# M2Sxxx register map
Vendor: Microsemi; Series: SmartFusion2; File version: 2.0.32
CPU: CM3 r2p1, little endian, MPU, no FPU, 4 interrupt priority bits
Registers are 32-bit, read-write, no defined reset value unless marked. A register's access mark holds for its fields unless they carry their own. Offsets are from the block's base; [hi:lo] are bit positions; {n}, {i} and the like mark numbered series.

## SERDES_0_SYS_REG — No description provided for this peripheral
Base 0x4002A000
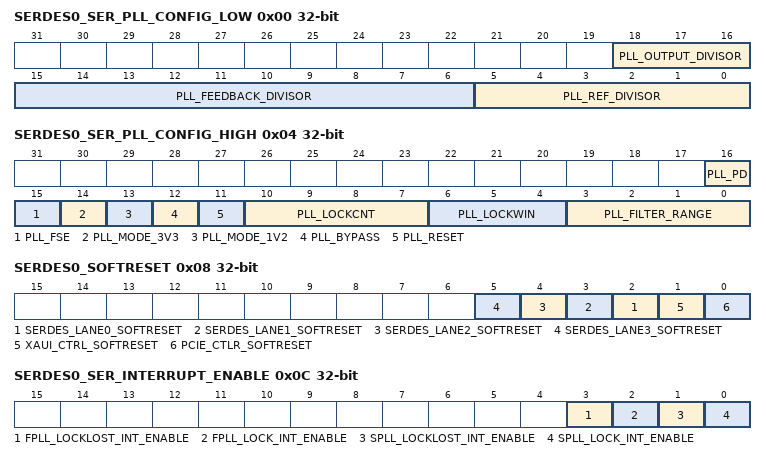
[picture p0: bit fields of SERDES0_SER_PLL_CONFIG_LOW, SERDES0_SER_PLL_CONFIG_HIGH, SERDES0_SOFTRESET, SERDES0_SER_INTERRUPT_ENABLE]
0x00 SERDES0_SER_PLL_CONFIG_LOW — No description provided for this register
  [18:16] PLL_OUTPUT_DIVISOR — No description provided for this field
  [15:6] PLL_FEEDBACK_DIVISOR — No description provided for this field
  [5:0] PLL_REF_DIVISOR — No description provided for this field
0x04 SERDES0_SER_PLL_CONFIG_HIGH — No description provided for this register
  [16] PLL_PD — No description provided for this field
  [15] PLL_FSE — No description provided for this field
  [14] PLL_MODE_3V3 — No description provided for this field
  [13] PLL_MODE_1V2 — No description provided for this field
  [12] PLL_BYPASS — No description provided for this field
  [11] PLL_RESET — No description provided for this field
  [10:7] PLL_LOCKCNT — No description provided for this field
  [6:4] PLL_LOCKWIN — No description provided for this field
  [3:0] PLL_FILTER_RANGE — No description provided for this field
0x08 SERDES0_SOFTRESET — No description provided for this register
  [n+2] SERDES_LANE{n}_SOFTRESET (n=0..3) — No description provided for this field
  [1] XAUI_CTRL_SOFTRESET — No description provided for this field
  [0] PCIE_CTLR_SOFTRESET — No description provided for this field
0x0C SERDES0_SER_INTERRUPT_ENABLE — No description provided for this register
  [3] FPLL_LOCKLOST_INT_ENABLE — No description provided for this field
  [2] FPLL_LOCK_INT_ENABLE — No description provided for this field
  [1] SPLL_LOCKLOST_INT_ENABLE — No description provided for this field
  [0] SPLL_LOCK_INT_ENABLE — No description provided for this field
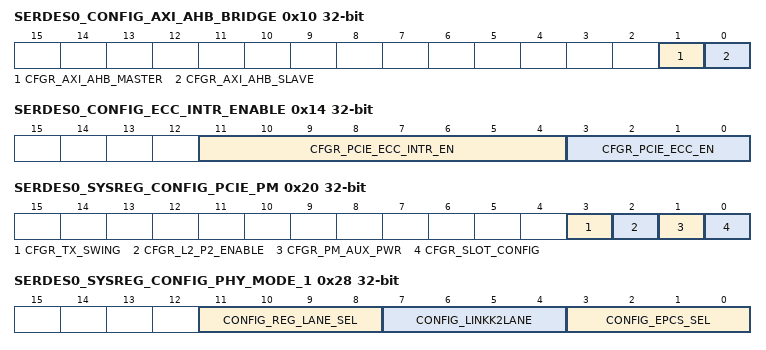
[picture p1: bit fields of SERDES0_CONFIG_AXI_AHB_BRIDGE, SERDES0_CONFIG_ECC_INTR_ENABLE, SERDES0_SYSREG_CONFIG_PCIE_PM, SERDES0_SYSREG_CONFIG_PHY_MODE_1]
0x10 SERDES0_CONFIG_AXI_AHB_BRIDGE — No description provided for this register
  [1] CFGR_AXI_AHB_MASTER — No description provided for this field
  [0] CFGR_AXI_AHB_SLAVE — No description provided for this field
0x14 SERDES0_CONFIG_ECC_INTR_ENABLE — No description provided for this register
  [11:4] CFGR_PCIE_ECC_INTR_EN — No description provided for this field
  [3:0] CFGR_PCIE_ECC_EN — No description provided for this field
0x20 SERDES0_SYSREG_CONFIG_PCIE_PM — No description provided for this register
  [3] CFGR_TX_SWING — No description provided for this field
  [2] CFGR_L2_P2_ENABLE — No description provided for this field
  [1] CFGR_PM_AUX_PWR — No description provided for this field
  [0] CFGR_SLOT_CONFIG — No description provided for this field
0x24 SERDES0_SYSREG_CONFIG_PHY_MODE_0 — No description provided for this register
  [15:0] CONFIG_PHY_MODE — No description provided for this field
0x28 SERDES0_SYSREG_CONFIG_PHY_MODE_1 — No description provided for this register
  [11:8] CONFIG_REG_LANE_SEL — No description provided for this field
  [7:4] CONFIG_LINKK2LANE — No description provided for this field
  [3:0] CONFIG_EPCS_SEL — No description provided for this field
0x2C SERDES0_SYSREG_CONFIG_PHY_MODE_2 — No description provided for this register
  [7:0] CONFIG_REXT_SEL — No description provided for this field
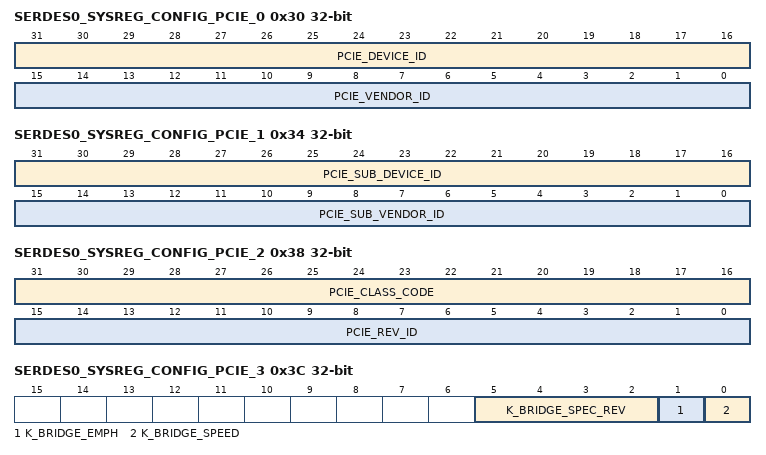
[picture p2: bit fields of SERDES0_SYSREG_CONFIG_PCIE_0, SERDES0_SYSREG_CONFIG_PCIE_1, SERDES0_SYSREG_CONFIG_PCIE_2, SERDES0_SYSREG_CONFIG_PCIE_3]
0x30 SERDES0_SYSREG_CONFIG_PCIE_0 — No description provided for this register
  [31:16] PCIE_DEVICE_ID — No description provided for this field
  [15:0] PCIE_VENDOR_ID — No description provided for this field
0x34 SERDES0_SYSREG_CONFIG_PCIE_1 — No description provided for this register
  [31:16] PCIE_SUB_DEVICE_ID — No description provided for this field
  [15:0] PCIE_SUB_VENDOR_ID — No description provided for this field
0x38 SERDES0_SYSREG_CONFIG_PCIE_2 — No description provided for this register
  [31:16] PCIE_CLASS_CODE — No description provided for this field
  [15:0] PCIE_REV_ID — No description provided for this field
0x3C SERDES0_SYSREG_CONFIG_PCIE_3 — No description provided for this register
  [5:2] K_BRIDGE_SPEC_REV — No description provided for this field
  [1] K_BRIDGE_EMPH — No description provided for this field
  [0] K_BRIDGE_SPEED — No description provided for this field
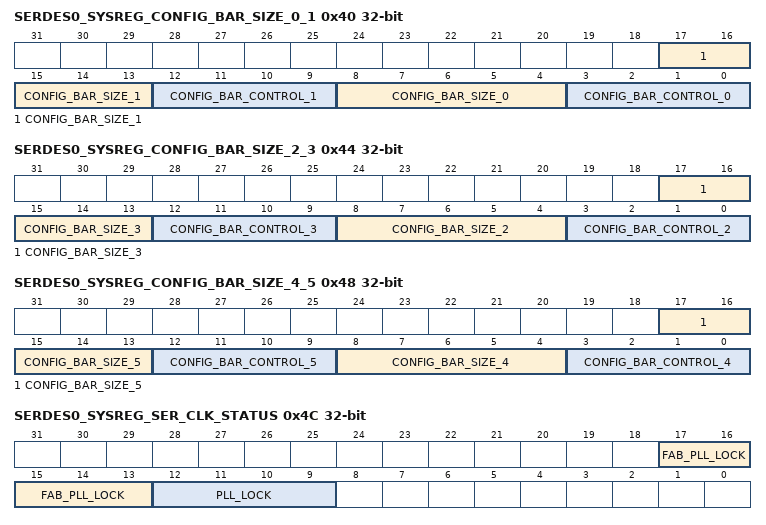
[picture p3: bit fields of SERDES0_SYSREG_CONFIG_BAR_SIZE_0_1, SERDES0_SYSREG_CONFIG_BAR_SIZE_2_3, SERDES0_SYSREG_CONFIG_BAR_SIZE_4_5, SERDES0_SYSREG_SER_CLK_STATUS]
0x40 SERDES0_SYSREG_CONFIG_BAR_SIZE_0_1 — No description provided for this register
  [17:13] CONFIG_BAR_SIZE_1 — No description provided for this field
  [12:9] CONFIG_BAR_CONTROL_1 — No description provided for this field
  [8:4] CONFIG_BAR_SIZE_0 — No description provided for this field
  [3:0] CONFIG_BAR_CONTROL_0 — No description provided for this field
0x44 SERDES0_SYSREG_CONFIG_BAR_SIZE_2_3 — No description provided for this register
  [17:13] CONFIG_BAR_SIZE_3 — No description provided for this field
  [12:9] CONFIG_BAR_CONTROL_3 — No description provided for this field
  [8:4] CONFIG_BAR_SIZE_2 — No description provided for this field
  [3:0] CONFIG_BAR_CONTROL_2 — No description provided for this field
0x48 SERDES0_SYSREG_CONFIG_BAR_SIZE_4_5 — No description provided for this register
  [17:13] CONFIG_BAR_SIZE_5 — No description provided for this field
  [12:9] CONFIG_BAR_CONTROL_5 — No description provided for this field
  [8:4] CONFIG_BAR_SIZE_4 — No description provided for this field
  [3:0] CONFIG_BAR_CONTROL_4 — No description provided for this field
0x4C SERDES0_SYSREG_SER_CLK_STATUS — No description provided for this register
  [17:13] FAB_PLL_LOCK — No description provided for this field
  [12:9] PLL_LOCK — No description provided for this field
0x50 SERDES0_SYSREG_SER_CLK_CALIB_STATUS — No description provided for this register
  [1:0] FABCALIBFAIL — No description provided for this field
0x54 SERDES0_TEST_OUT_READ_DATA — No description provided for this register
  [31:0] TEST_OUT_READ_DATA — No description provided for this field
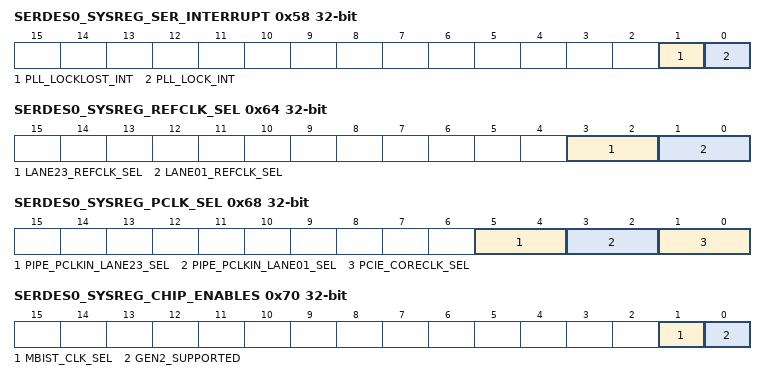
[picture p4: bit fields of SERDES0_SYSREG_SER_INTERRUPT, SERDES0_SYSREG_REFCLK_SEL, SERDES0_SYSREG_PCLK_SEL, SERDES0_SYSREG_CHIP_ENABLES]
0x58 SERDES0_SYSREG_SER_INTERRUPT — No description provided for this register
  [1] PLL_LOCKLOST_INT — No description provided for this field
  [0] PLL_LOCK_INT — No description provided for this field
0x5C SERDES0_SYSREG_SERDESIF_INTR_STATUS — No description provided for this register
  [5:0] SERDESIF_INTR_STATUS — No description provided for this field
0x60 SERDES0_SER_CLK_CALIB_CONFIG — No description provided for this register
  [1:0] FABCALIBSTART — No description provided for this field
0x64 SERDES0_SYSREG_REFCLK_SEL — No description provided for this register
  [3:2] LANE23_REFCLK_SEL — No description provided for this field
  [1:0] LANE01_REFCLK_SEL — No description provided for this field
0x68 SERDES0_SYSREG_PCLK_SEL — No description provided for this register
  [5:4] PIPE_PCLKIN_LANE23_SEL — No description provided for this field
  [3:2] PIPE_PCLKIN_LANE01_SEL — No description provided for this field
  [1:0] PCIE_CORECLK_SEL — No description provided for this field
0x6C SERDES0_SYSREG_EPCS_RSTN_SEL — No description provided for this register
  [3:0] FABRIC_EPCS_RSTN_SEL — No description provided for this field
0x70 SERDES0_SYSREG_CHIP_ENABLES — No description provided for this register
  [1] MBIST_CLK_SEL — No description provided for this field
  [0] GEN2_SUPPORTED — No description provided for this field
0x74 SERDES0_SYSREG_SERDES_TEST_OUT — No description provided for this register
  [31:0] SERDES_TEST_OUT — No description provided for this field
0x7C SERDES0_SYSREG_RC_OSC_SPLL_REFCLK_SEL — No description provided for this register
  [0] RC_OSC_REFCLK_SEL — No description provided for this field
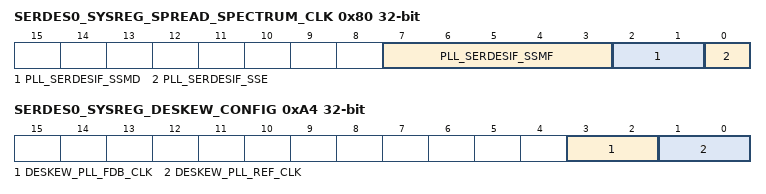
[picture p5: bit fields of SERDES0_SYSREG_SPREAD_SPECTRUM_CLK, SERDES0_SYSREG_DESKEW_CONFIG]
0x80 SERDES0_SYSREG_SPREAD_SPECTRUM_CLK — No description provided for this register
  [7:3] PLL_SERDESIF_SSMF — No description provided for this field
  [2:1] PLL_SERDESIF_SSMD — No description provided for this field
  [0] PLL_SERDESIF_SSE — No description provided for this field
{0x84+4i} SERDES0_SYSREG_CONF_AXI_MSTR_WNDW_{i} (i=0..2) — No description provided for this register
  [31:0] CONF_AXI_MSTR_WNDW_{i} — No description provided for this field
0x90 SERDES0_SYSREG_CONF_AXI_MSTR_WNDW_3 — No description provided for this register
  [3:0] CONF_AXI_MSTR_WNDW_3 — No description provided for this field
{0x94+4i} SERDES0_SYSREG_CONF_AXI_SLV_WNDW_{i} (i=0..2) — No description provided for this register
  [31:0] CONF_AXI_SLV_WNDW_{i} — No description provided for this field
0xA0 SERDES0_SYSREG_CONF_AXI_SLV_WNDW_3 — No description provided for this register
  [3:0] CONF_AXI_SLV_WNDW_3 — No description provided for this field
0xA4 SERDES0_SYSREG_DESKEW_CONFIG — No description provided for this register
  [3:2] DESKEW_PLL_FDB_CLK — No description provided for this field
  [1:0] DESKEW_PLL_REF_CLK — No description provided for this field
0xA8 SERDES0_DEBUG_MODE_KEY — No description provided for this register
  [7:0] DEBUG_MODE_KEY — No description provided for this field
0xAC SERDES0_ATSPEED_CLK_SEL — No description provided for this register
  [0] ATSPEED_CLK_SEL — No description provided for this field
0xB0 SERDES0_EXTRA_BITS — No description provided for this register
  [7:0] EXTRA_BITS — No description provided for this field
